# STM32U385 register map
File version: 1.0
CPU: CM33 r0p1, little endian, MPU, FPU, 4 interrupt priority bits
Registers are 32-bit, read-write, reset 0x0 unless marked. A register's access mark holds for its fields unless they carry their own. Offsets are from the block's base; [hi:lo] are bit positions.

## GTZC1_TZSC — GTZC1_TZSC Address block
Base 0x40032400
Same registers: SEC_GTZC1_TZSC 0x50032400
0x00 GTZC1_TZSC_CR — GTZC1 TZSC control register
  [0] LCK — This bit is cleared by default and once set, it can not be reset until system reset. 0: configuration of all GTZC1_TZSC_SECCFGRx and GTZC1_TZSC_PRIVCFGRx registers not locked 1: configuration of all GTZC1_TZSC_SECCFGRx and GTZC1_TZSC_PRIVCFGRx registers locked
    0=configuration of all GTZC1_TZSC_SECCFGRx and GTZC1_TZSC_PRIVCFGRx registers not locked; 1=configuration of all GTZC1_TZSC_SECCFGRx and GTZC1_TZSC_PRIVCFGRx registers locked
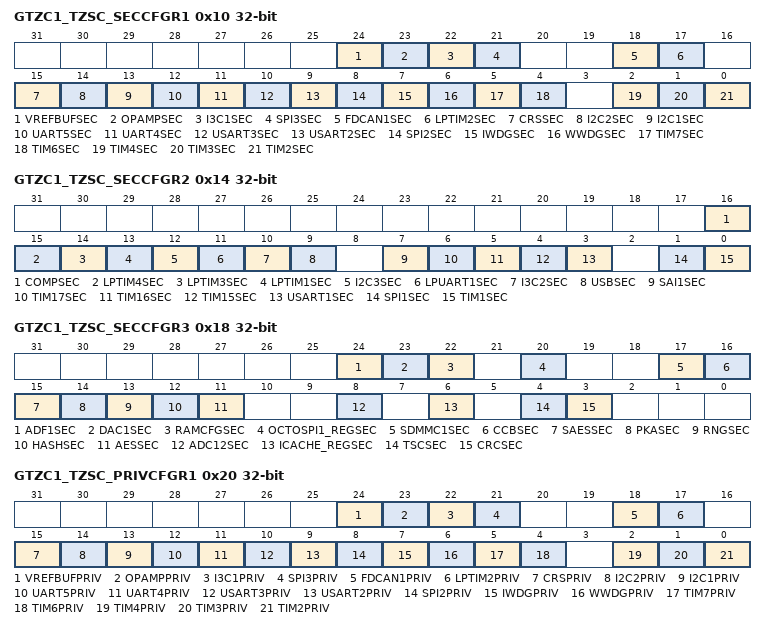
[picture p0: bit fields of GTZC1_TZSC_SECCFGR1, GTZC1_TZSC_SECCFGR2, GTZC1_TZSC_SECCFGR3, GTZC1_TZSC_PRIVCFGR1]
0x10 GTZC1_TZSC_SECCFGR1 — GTZC1 TZSC secure configuration register 1
  [all] fields
    0=non-secure; 1=secure
  [24] VREFBUFSEC — 0: non-secure 1: secure
  [23] OPAMPSEC — 0: non-secure 1: secure
  [22] I3C1SEC — 0: non-secure 1: secure
  [21] SPI3SEC — 0: non-secure 1: secure
  [18] FDCAN1SEC — 0: non-secure 1: secure
  [17] LPTIM2SEC — 0: non-secure 1: secure
  [15] CRSSEC — 0: non-secure 1: secure
  [14] I2C2SEC — 0: non-secure 1: secure
  [13] I2C1SEC — 0: non-secure 1: secure
  [12] UART5SEC — 0: non-secure 1: secure
  [11] UART4SEC — 0: non-secure 1: secure
  [10] USART3SEC — 0: non-secure 1: secure
  [9] USART2SEC — 0: non-secure 1: secure
  [8] SPI2SEC — 0: non-secure 1: secure
  [7] IWDGSEC — 0: non-secure 1: secure
  [6] WWDGSEC — 0: non-secure 1: secure
  [5] TIM7SEC — 0: non-secure 1: secure
  [4] TIM6SEC — 0: non-secure 1: secure
  [2] TIM4SEC — 0: non-secure 1: secure
  [1] TIM3SEC — 0: non-secure 1: secure
  [0] TIM2SEC — 0: non-secure 1: secure
0x14 GTZC1_TZSC_SECCFGR2 — GTZC1 TZSC secure configuration register 2
  [all] fields
    0=non-secure; 1=secure
  [16] COMPSEC — 0: non-secure 1: secure
  [15] LPTIM4SEC — 0: non-secure 1: secure
  [14] LPTIM3SEC — 0: non-secure 1: secure
  [13] LPTIM1SEC — 0: non-secure 1: secure
  [12] I2C3SEC — 0: non-secure 1: secure
  [11] LPUART1SEC — 0: non-secure 1: secure
  [10] I3C2SEC — 0: non-secure 1: secure
  [9] USBSEC — 0: non-secure 1: secure
  [7] SAI1SEC — 0: non-secure 1: secure
  [6] TIM17SEC — 0: non-secure 1: secure
  [5] TIM16SEC — 0: non-secure 1: secure
  [4] TIM15SEC — 0: non-secure 1: secure
  [3] USART1SEC — 0: non-secure 1: secure
  [1] SPI1SEC — 0: non-secure 1: secure
  [0] TIM1SEC — 0: non-secure 1: secure
0x18 GTZC1_TZSC_SECCFGR3 — GTZC1 TZSC secure configuration register 3
  [all] fields
    0=non-secure; 1=secure
  [24] ADF1SEC — 0: non-secure 1: secure
  [23] DAC1SEC — 0: non-secure 1: secure
  [22] RAMCFGSEC — 0: non-secure 1: secure
  [20] OCTOSPI1_REGSEC — 0: non-secure 1: secure
  [17] SDMMC1SEC — 0: non-secure 1: secure
  [16] CCBSEC — 0: non-secure 1: secure
  [15] SAESSEC — 0: non-secure 1: secure
  [14] PKASEC — 0: non-secure 1: secure
  [13] RNGSEC — 0: non-secure 1: secure
  [12] HASHSEC — 0: non-secure 1: secure
  [11] AESSEC — 0: non-secure 1: secure
  [8] ADC12SEC — 0: non-secure 1: secure
  [6] ICACHE_REGSEC — 0: non-secure 1: secure
  [4] TSCSEC — 0: non-secure 1: secure
  [3] CRCSEC — 0: non-secure 1: secure
0x20 GTZC1_TZSC_PRIVCFGR1 — GTZC1 TZSC privilege configuration register 1
  [all] fields
    0=unprivileged; 1=privileged
  [24] VREFBUFPRIV — 0: unprivileged 1: privileged
  [23] OPAMPPRIV — 0: unprivileged 1: privileged
  [22] I3C1PRIV — 0: unprivileged 1: privileged
  [21] SPI3PRIV — 0: unprivileged 1: privileged
  [18] FDCAN1PRIV — 0: unprivileged 1: privileged
  [17] LPTIM2PRIV — 0: unprivileged 1: privileged
  [15] CRSPRIV — 0: unprivileged 1: privileged
  [14] I2C2PRIV — 0: unprivileged 1: privileged
  [13] I2C1PRIV — 0: unprivileged 1: privileged
  [12] UART5PRIV — 0: unprivileged 1: privileged
  [11] UART4PRIV — 0: unprivileged 1: privileged
  [10] USART3PRIV — 0: unprivileged 1: privileged
  [9] USART2PRIV — 0: unprivileged 1: privileged
  [8] SPI2PRIV — 0: unprivileged 1: privileged
  [7] IWDGPRIV — 0: unprivileged 1: privileged
  [6] WWDGPRIV — 0: unprivileged 1: privileged
  [5] TIM7PRIV — 0: unprivileged 1: privileged
  [4] TIM6PRIV — 0: unprivileged 1: privileged
  [2] TIM4PRIV — 0: unprivileged 1: privileged
  [1] TIM3PRIV — 0: unprivileged 1: privileged
  [0] TIM2PRIV — 0: unprivileged 1: privileged
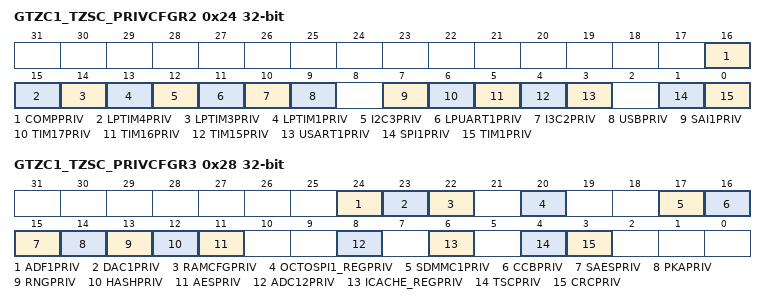
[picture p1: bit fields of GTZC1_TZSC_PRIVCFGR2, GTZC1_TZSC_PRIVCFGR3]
0x24 GTZC1_TZSC_PRIVCFGR2 — GTZC1 TZSC privilege configuration register 2
  [all] fields
    0=unprivileged; 1=privileged
  [16] COMPPRIV — 0: unprivileged 1: privileged
  [15] LPTIM4PRIV — 0: unprivileged 1: privileged
  [14] LPTIM3PRIV — 0: unprivileged 1: privileged
  [13] LPTIM1PRIV — 0: unprivileged 1: privileged
  [12] I2C3PRIV — 0: unprivileged 1: privileged
  [11] LPUART1PRIV — 0: unprivileged 1: privileged
  [10] I3C2PRIV — 0: unprivileged 1: privileged
  [9] USBPRIV — 0: unprivileged 1: privileged
  [7] SAI1PRIV — 0: unprivileged 1: privileged
  [6] TIM17PRIV — 0: unprivileged 1: privileged
  [5] TIM16PRIV — 0: unprivileged 1: privileged
  [4] TIM15PRIV — 0: unprivileged 1: privileged
  [3] USART1PRIV — 0: unprivileged 1: privileged
  [1] SPI1PRIV — 0: unprivileged 1: privileged
  [0] TIM1PRIV — 0: unprivileged 1: privileged
0x28 GTZC1_TZSC_PRIVCFGR3 — GTZC1 TZSC privilege configuration register 3
  [all] fields
    0=unprivileged; 1=privileged
  [24] ADF1PRIV — 0: unprivileged 1: privileged
  [23] DAC1PRIV — 0: unprivileged 1: privileged
  [22] RAMCFGPRIV — 0: unprivileged 1: privileged
  [20] OCTOSPI1_REGPRIV — 0: unprivileged 1: privileged
  [17] SDMMC1PRIV — 0: unprivileged 1: privileged
  [16] CCBPRIV — 0: unprivileged 1: privileged
  [15] SAESPRIV — 0: unprivileged 1: privileged
  [14] PKAPRIV — 0: unprivileged 1: privileged
  [13] RNGPRIV — 0: unprivileged 1: privileged
  [12] HASHPRIV — 0: unprivileged 1: privileged
  [11] AESPRIV — 0: unprivileged 1: privileged
  [8] ADC12PRIV — 0: unprivileged 1: privileged
  [6] ICACHE_REGPRIV — 0: unprivileged 1: privileged
  [4] TSCPRIV — 0: unprivileged 1: privileged
  [3] CRCPRIV — 0: unprivileged 1: privileged
